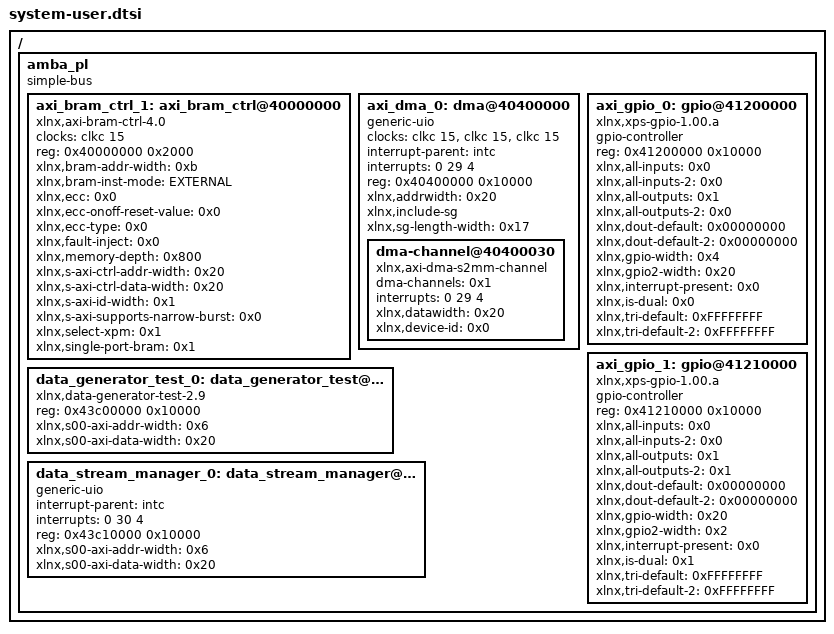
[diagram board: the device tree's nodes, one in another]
/include/ "system-conf.dtsi"
/ {
	amba_pl: amba_pl {
		#address-cells = <1>;
		#size-cells = <1>;
		compatible = "simple-bus";
		ranges ;
		axi_bram_ctrl_1: axi_bram_ctrl@40000000 {
			clock-names = "s_axi_aclk";
			clocks = <&clkc 15>;
			compatible = "xlnx,axi-bram-ctrl-4.0";
			reg = <0x40000000 0x2000>;
			xlnx,bram-addr-width = <0xb>;
			xlnx,bram-inst-mode = "EXTERNAL";
			xlnx,ecc = <0x0>;
			xlnx,ecc-onoff-reset-value = <0x0>;
			xlnx,ecc-type = <0x0>;
			xlnx,fault-inject = <0x0>;
			xlnx,memory-depth = <0x800>;
			xlnx,s-axi-ctrl-addr-width = <0x20>;
			xlnx,s-axi-ctrl-data-width = <0x20>;
			xlnx,s-axi-id-width = <0x1>;
			xlnx,s-axi-supports-narrow-burst = <0x0>;
			xlnx,select-xpm = <0x1>;
			xlnx,single-port-bram = <0x1>;
		};
		axi_dma_0: dma@40400000 {
			#dma-cells = <1>;
			clock-names = "s_axi_lite_aclk", "m_axi_sg_aclk", "m_axi_s2mm_aclk";
			clocks = <&clkc 15>, <&clkc 15>, <&clkc 15>;
			compatible = "generic-uio";
			interrupt-names = "s2mm_introut";
			interrupt-parent = <&intc>;
			interrupts = <0 29 4>;
			reg = <0x40400000 0x10000>;
			xlnx,addrwidth = <0x20>;
			xlnx,include-sg ;
			xlnx,sg-length-width = <0x17>;
			dma-channel@40400030 {
				compatible = "xlnx,axi-dma-s2mm-channel";
				dma-channels = <0x1>;
				interrupts = <0 29 4>;
				xlnx,datawidth = <0x20>;
				xlnx,device-id = <0x0>;
			};
		};
		axi_gpio_0: gpio@41200000 {
			#gpio-cells = <2>;
			compatible = "xlnx,xps-gpio-1.00.a";
			gpio-controller ;
			reg = <0x41200000 0x10000>;
			xlnx,all-inputs = <0x0>;
			xlnx,all-inputs-2 = <0x0>;
			xlnx,all-outputs = <0x1>;
			xlnx,all-outputs-2 = <0x0>;
			xlnx,dout-default = <0x00000000>;
			xlnx,dout-default-2 = <0x00000000>;
			xlnx,gpio-width = <0x4>;
			xlnx,gpio2-width = <0x20>;
			xlnx,interrupt-present = <0x0>;
			xlnx,is-dual = <0x0>;
			xlnx,tri-default = <0xFFFFFFFF>;
			xlnx,tri-default-2 = <0xFFFFFFFF>;
		};
		axi_gpio_1: gpio@41210000 {
			#gpio-cells = <2>;
			compatible = "xlnx,xps-gpio-1.00.a";
			gpio-controller ;
			reg = <0x41210000 0x10000>;
			xlnx,all-inputs = <0x0>;
			xlnx,all-inputs-2 = <0x0>;
			xlnx,all-outputs = <0x1>;
			xlnx,all-outputs-2 = <0x1>;
			xlnx,dout-default = <0x00000000>;
			xlnx,dout-default-2 = <0x00000000>;
			xlnx,gpio-width = <0x20>;
			xlnx,gpio2-width = <0x2>;
			xlnx,interrupt-present = <0x0>;
			xlnx,is-dual = <0x1>;
			xlnx,tri-default = <0xFFFFFFFF>;
			xlnx,tri-default-2 = <0xFFFFFFFF>;
		};
		axi_bram_ctrl_1: axi_bram_ctrl@40000000 {
			compatible = "xlnx,axi-bram-ctrl-4.0";
			reg = <0x40000000 0x2000>;
			xlnx,bram-addr-width = <0xb>;
			xlnx,bram-inst-mode = "EXTERNAL";
			xlnx,ecc = <0x0>;
			xlnx,ecc-onoff-reset-value = <0x0>;
			xlnx,ecc-type = <0x0>;
			xlnx,fault-inject = <0x0>;
			xlnx,memory-depth = <0x800>;
			xlnx,s-axi-ctrl-addr-width = <0x20>;
			xlnx,s-axi-ctrl-data-width = <0x20>;
			xlnx,s-axi-id-width = <0x1>;
			xlnx,s-axi-supports-narrow-burst = <0x0>;
			xlnx,select-xpm = <0x1>;
			xlnx,single-port-bram = <0x1>;
		};
		data_generator_test_0: data_generator_test@43c00000 {
			compatible = "xlnx,data-generator-test-2.9";
			reg = <0x43c00000 0x10000>;
			xlnx,s00-axi-addr-width = <0x6>;
			xlnx,s00-axi-data-width = <0x20>;
		};
		data_stream_manager_0: data_stream_manager@43c10000 {
			compatible = "generic-uio";
			interrupt-parent = <&intc>;
			interrupts = <0 30 4>;
			reg = <0x43c10000 0x10000>;
			xlnx,s00-axi-addr-width = <0x6>;
			xlnx,s00-axi-data-width = <0x20>;
		};
	};
};
